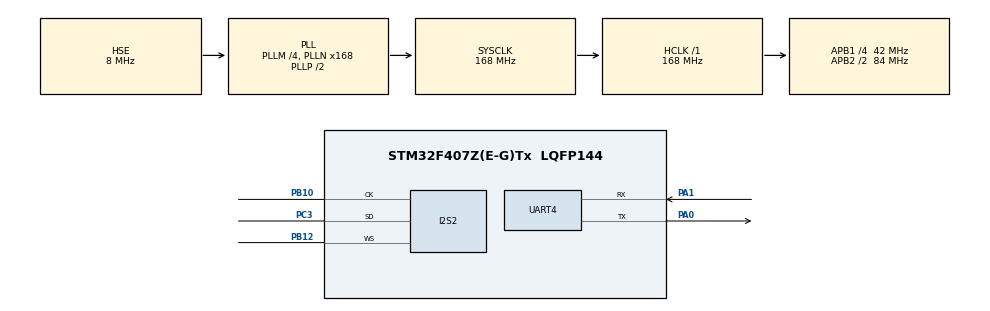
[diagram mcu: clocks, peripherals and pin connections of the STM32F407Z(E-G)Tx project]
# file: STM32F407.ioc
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Dma.Request0=SPI2_TX
Dma.SPI2_TX.0.Direction=DMA_MEMORY_TO_PERIPH
Dma.SPI2_TX.0.FIFOMode=DMA_FIFOMODE_DISABLE
Dma.SPI2_TX.0.Instance=DMA1_Stream4
Dma.SPI2_TX.0.MemDataAlignment=DMA_MDATAALIGN_WORD
Dma.SPI2_TX.0.MemInc=DMA_MINC_ENABLE
Dma.SPI2_TX.0.Mode=DMA_CIRCULAR
Dma.SPI2_TX.0.PeriphDataAlignment=DMA_PDATAALIGN_WORD
Dma.SPI2_TX.0.PeriphInc=DMA_PINC_DISABLE
Dma.SPI2_TX.0.Priority=DMA_PRIORITY_LOW
I2S2.AudioFreq=I2S_AUDIOFREQ_16K
I2S2.DataFormat=I2S_DATAFORMAT_24B
I2S2.ErrorAudioFreq=-0.26 %
I2S2.FullDuplexMode=I2S_FULLDUPLEXMODE_DISABLE
I2S2.Instance=SPI$Index
I2S2.RealAudioFreq=15.957 KHz
I2S2.VirtualMode=I2S_MODE_MASTER
Mcu.Family=STM32F4
Mcu.Name=STM32F407Z(E-G)Tx
Mcu.Package=LQFP144
NVIC.DMA1_Stream4_IRQn=true\:0\:0\:false\:false\:true\:false\:true\:true
NVIC.PriorityGroup=NVIC_PRIORITYGROUP_4
PA0-WKUP.Mode=Asynchronous
PA0-WKUP.Signal=UART4_TX
PA1.Mode=Asynchronous
PA1.Signal=UART4_RX
PA13.Mode=Serial_Wire
PA13.Signal=SYS_JTMS-SWDIO
PA14.Mode=Serial_Wire
PA14.Signal=SYS_JTCK-SWCLK
PB10.Mode=Half_Duplex_Master
PB10.Signal=I2S2_CK
PB12.Mode=Half_Duplex_Master
PB12.Signal=I2S2_WS
PC3.Mode=Half_Duplex_Master
PC3.Signal=I2S2_SD
PH0-OSC_IN.Mode=HSE-External-Oscillator
PH0-OSC_IN.Signal=RCC_OSC_IN
PH1-OSC_OUT.Mode=HSE-External-Oscillator
PH1-OSC_OUT.Signal=RCC_OSC_OUT
ProjectManager.HeapSize=0x800
ProjectManager.StackSize=0x800
ProjectManager.TargetToolchain=STM32CubeIDE
RCC.48MHZClocksFreq_Value=84000000
RCC.AHBFreq_Value=168000000
RCC.APB1CLKDivider=RCC_HCLK_DIV4
RCC.APB1Freq_Value=42000000
RCC.APB1TimFreq_Value=84000000
RCC.APB2CLKDivider=RCC_HCLK_DIV2
RCC.APB2Freq_Value=84000000
RCC.APB2TimFreq_Value=168000000
RCC.CortexFreq_Value=168000000
RCC.EnbaleCSS=true
RCC.HCLKFreq_Value=168000000
RCC.HSE_VALUE=8000000
RCC.HSI_VALUE=16000000
RCC.LSE_VALUE=32768
RCC.PLLM=4
RCC.PLLN=168
RCC.PLLSourceVirtual=RCC_PLLSOURCE_HSE
RCC.SYSCLKFreq_VALUE=168000000
RCC.SYSCLKSource=RCC_SYSCLKSOURCE_PLLCLK
RCC.VCOOutputFreq_Value=336000000
STMicroelectronics.X-CUBE-AI.10.0.0.ActivationBufferSizeList=133516
STMicroelectronics.X-CUBE-AI.10.0.0.ActivationBuffers=pool0
STMicroelectronics.X-CUBE-AI.10.0.0.ActivationNames=pool0
STMicroelectronics.X-CUBE-AI.10.0.0.ActivationSizes=AI_NETWORK_DATA_ACTIVATION_1_SIZE
STMicroelectronics.X-CUBE-AI.10.0.0.HeapSize=0x800
STMicroelectronics.X-CUBE-AI.10.0.0.InternalRamActivationBufferMaxSize=AI_NETWORK_DATA_ACTIVATIONS_SIZE
STMicroelectronics.X-CUBE-AI.10.0.0.LatestDirectoryUsed-52d1d453d7fa0c1e5a27128fe81fe88caa618f2502dde61aea7d7957c0252891=C\:\\GitHub\\voiceprint_recognition\\models\\voiceprint_model
STMicroelectronics.X-CUBE-AI.10.0.0.MaximumNumberOfInputLayer=1
STMicroelectronics.X-CUBE-AI.10.0.0.MaximumNumberOfOutputLayer=1
STMicroelectronics.X-CUBE-AI.10.0.0.MaximumSizeOfInputLayer=1
STMicroelectronics.X-CUBE-AI.10.0.0.MaximumSizeOfOutputLayer=1
STMicroelectronics.X-CUBE-AI.10.0.0.ModelActualCompression-52d1d453d7fa0c1e5a27128fe81fe88caa618f2502dde61aea7d7957c0252891=0.0
STMicroelectronics.X-CUBE-AI.10.0.0.ModelCompression-52d1d453d7fa0c1e5a27128fe81fe88caa618f2502dde61aea7d7957c0252891=None
STMicroelectronics.X-CUBE-AI.10.0.0.ModelFlashOccupation-52d1d453d7fa0c1e5a27128fe81fe88caa618f2502dde61aea7d7957c0252891=230128
STMicroelectronics.X-CUBE-AI.10.0.0.ModelHashList=52d1d453d7fa0c1e5a27128fe81fe88caa618f2502dde61aea7d7957c0252891;d7917eb620960ccd5fc1a639df0c189e980c944b18d2a58c163e27e3a9fc462d
STMicroelectronics.X-CUBE-AI.10.0.0.ModelKind-52d1d453d7fa0c1e5a27128fe81fe88caa618f2502dde61aea7d7957c0252891=TFLITE
STMicroelectronics.X-CUBE-AI.10.0.0.ModelMacc-52d1d453d7fa0c1e5a27128fe81fe88caa618f2502dde61aea7d7957c0252891=33718160
STMicroelectronics.X-CUBE-AI.10.0.0.ModelName-52d1d453d7fa0c1e5a27128fe81fe88caa618f2502dde61aea7d7957c0252891=network
STMicroelectronics.X-CUBE-AI.10.0.0.ModelNameList=network,network_2
STMicroelectronics.X-CUBE-AI.10.0.0.ModelRamOccupation-52d1d453d7fa0c1e5a27128fe81fe88caa618f2502dde61aea7d7957c0252891=133516
STMicroelectronics.X-CUBE-AI.10.0.0.ModelStructureFile-52d1d453d7fa0c1e5a27128fe81fe88caa618f2502dde61aea7d7957c0252891=/C\:/GitHub/voiceprint_recognition/models/voiceprint_model/voiceprint_model.tflite
STMicroelectronics.X-CUBE-AI.10.0.0.ModelType-52d1d453d7fa0c1e5a27128fe81fe88caa618f2502dde61aea7d7957c0252891=STM32Cube.AI MCU runtime
STMicroelectronics.X-CUBE-AI.10.0.0.ReadyForCodeGeneration=true
STMicroelectronics.X-CUBE-AI.10.0.0.StackSize=0x800
STMicroelectronics.X-CUBE-AI.10.0.0.WorkingBufferStartAddrList=0xFFFFFFFF,0xFFFFFFFF
STMicroelectronics.X-CUBE-AI.10.0.0.XAaCUBEAaAICcArtificialOoIntelligenceJjCore=true
STMicroelectronics.X-CUBE-AI.10.0.0.copyWeightToRam=false
STMicroelectronics.X-CUBE-AI.10.0.0.customLayerConfigEnabled=false
STMicroelectronics.X-CUBE-AI.10.0.0.noOnnxIoTranspose=false
STMicroelectronics.X-CUBE-AI.10.0.0.useInputAllocation=true
STMicroelectronics.X-CUBE-AI.10.0.0.useOutputAllocation=true
UART4.VirtualMode=Asynchronous
VP_STMicroelectronics.X-CUBE-AI_VS_ArtificialOoIntelligenceJjXAaCUBEAaAI_10.0.0.Mode=ArtificialOoIntelligenceJjXAaCUBEAaAI
board=custom

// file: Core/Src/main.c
/* USER CODE BEGIN Header */
/**
  ******************************************************************************
  * @file           : main.c
  * @brief          : Main program body
  ******************************************************************************
  * @attention
  *
  * Copyright (c) 2025 STMicroelectronics.
  * All rights reserved.
  *
  * This software is licensed under terms that can be found in the LICENSE file
  * in the root directory of this software component.
  * If no LICENSE file comes with this software, it is provided AS-IS.
  *
  ******************************************************************************
  */
/* USER CODE END Header */
#include "main.h"
#include "dma.h"
#include "i2s.h"
#include "usart.h"
#include "gpio.h"

/* USER CODE BEGIN Includes */
#include "inmp441.h"
/* USER CODE END Includes */

void SystemClock_Config(void);

int main(void)
{

  /* MCU Configuration--------------------------------------------------------*/

  /* Reset of all peripherals, Initializes the Flash interface and the Systick. */
  HAL_Init();

  /* Configure the system clock */
  SystemClock_Config();

  /* Initialize all configured peripherals */
  MX_GPIO_Init();
  MX_DMA_Init();
  MX_I2S2_Init();
  MX_UART4_Init();
  /* USER CODE BEGIN 2 */
  HAL_I2S_Receive_DMA(&hi2s2,(uint16_t*)dma,4);
  /* USER CODE END 2 */

  /* Infinite loop */
  while (1)
  {

  }
}

void SystemClock_Config(void)
{
  RCC_OscInitTypeDef RCC_OscInitStruct = {0};
  RCC_ClkInitTypeDef RCC_ClkInitStruct = {0};

  /** Configure the main internal regulator output voltage
  */
  __HAL_RCC_PWR_CLK_ENABLE();
  __HAL_PWR_VOLTAGESCALING_CONFIG(PWR_REGULATOR_VOLTAGE_SCALE1);

  /** Initializes the RCC Oscillators according to the specified parameters
  * in the RCC_OscInitTypeDef structure.
  */
  RCC_OscInitStruct.OscillatorType = RCC_OSCILLATORTYPE_HSE;
  RCC_OscInitStruct.HSEState = RCC_HSE_ON;
  RCC_OscInitStruct.PLL.PLLState = RCC_PLL_ON;
  RCC_OscInitStruct.PLL.PLLSource = RCC_PLLSOURCE_HSE;
  RCC_OscInitStruct.PLL.PLLM = 4;
  RCC_OscInitStruct.PLL.PLLN = 168;
  RCC_OscInitStruct.PLL.PLLP = RCC_PLLP_DIV2;
  RCC_OscInitStruct.PLL.PLLQ = 4;
  if (HAL_RCC_OscConfig(&RCC_OscInitStruct) != HAL_OK)
  {
    Error_Handler();
  }

  /** Initializes the CPU, AHB and APB buses clocks
  */
  RCC_ClkInitStruct.ClockType = RCC_CLOCKTYPE_HCLK|RCC_CLOCKTYPE_SYSCLK
                              |RCC_CLOCKTYPE_PCLK1|RCC_CLOCKTYPE_PCLK2;
  RCC_ClkInitStruct.SYSCLKSource = RCC_SYSCLKSOURCE_PLLCLK;
  RCC_ClkInitStruct.AHBCLKDivider = RCC_SYSCLK_DIV1;
  RCC_ClkInitStruct.APB1CLKDivider = RCC_HCLK_DIV4;
  RCC_ClkInitStruct.APB2CLKDivider = RCC_HCLK_DIV2;

  if (HAL_RCC_ClockConfig(&RCC_ClkInitStruct, FLASH_LATENCY_5) != HAL_OK)
  {
    Error_Handler();
  }

  /** Enables the Clock Security System
  */
  HAL_RCC_EnableCSS();
}

void Error_Handler(void)
{
  __disable_irq();
  while (1)
  {
  }
}
